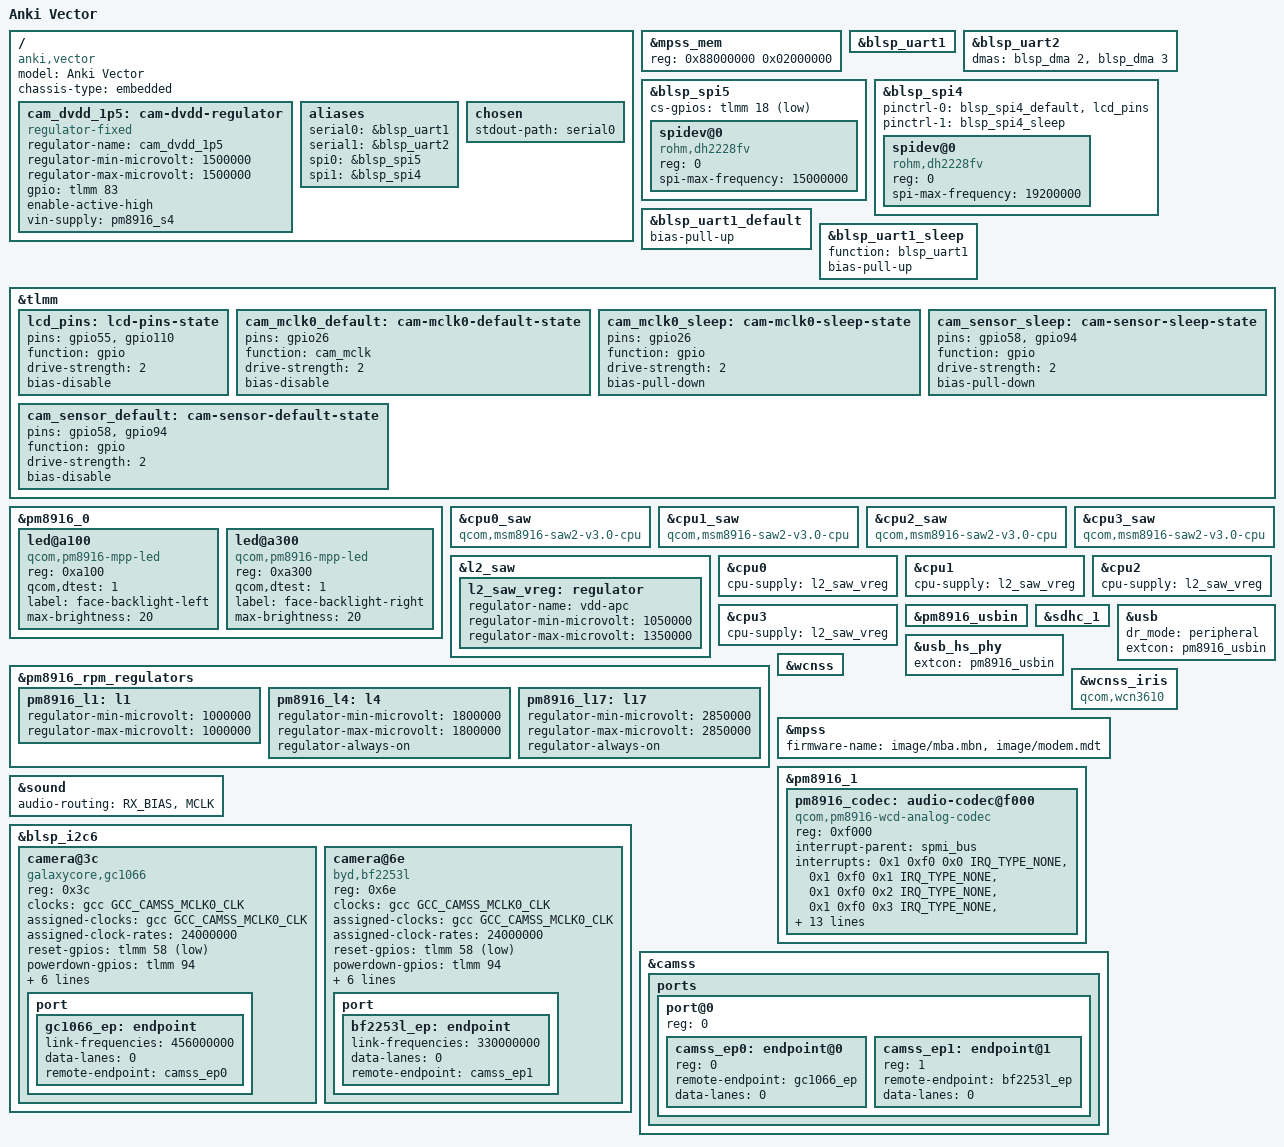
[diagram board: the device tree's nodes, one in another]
// SPDX-License-Identifier: GPL-2.0-only

/dts-v1/;

#include "qcom-msm8909-pm8916.dtsi"
#include "qcom-apq8009-modem-qdsp6.dtsi"

#include <dt-bindings/clock/qcom,gcc-msm8909.h>
#include <dt-bindings/gpio/gpio.h>
#include <dt-bindings/input/input.h>
#include <dt-bindings/interrupt-controller/irq.h>
#include <dt-bindings/leds/common.h>
#include <dt-bindings/pinctrl/qcom,pmic-mpp.h>

/ {
	model = "Anki Vector";
	compatible = "anki,vector", "qcom,msm8909";
	chassis-type = "embedded";

	// there's an external regulator for the camera
	// i can't say i understand why
	// S4 is 2.05V, VOUT (cam VDD) is 1.50V
	// GPIO 83 -> EN
	cam_dvdd_1p5: cam-dvdd-regulator {
		compatible = "regulator-fixed";
		regulator-name = "cam_dvdd_1p5";
		regulator-min-microvolt = <1500000>;
		regulator-max-microvolt = <1500000>;
		gpio = <&tlmm 83 GPIO_ACTIVE_HIGH>;
		enable-active-high;
		vin-supply = <&pm8916_s4>;
	};

	aliases {
		serial0 = &blsp_uart1; // kernel logs and shell
		serial1 = &blsp_uart2; // body
		spi0 = &blsp_spi5; // imu
		spi1 = &blsp_spi4; // lcd
	};

	chosen {
		#address-cells = <1>;
		#size-cells = <1>;
		ranges;

		stdout-path = "serial0";
	};
};

// the original firmware spanned EIGHTY FIVE MEGABYTES
// the firmware itself isn't this big, but it includes addresses which span this much
&mpss_mem {
	reg = <0x88000000 0x02000000>; // 32MB
};

// &bimc {
// 	status = "disabled";
// };

// &gcc {
// 	assigned-clocks = <&gcc BIMC_DDR_CLK_SRC>;
// 	assigned-clock-rates = <400000000>;
// };

&blsp_uart1 {
	status = "okay";
};

&blsp_uart2 {
	status = "okay";

	dmas = <&blsp_dma 2>, <&blsp_dma 3>;
	dma-names = "tx", "rx";
};

// imu
&blsp_spi5 {
	status = "okay";
	cs-gpios = <&tlmm 18 GPIO_ACTIVE_LOW>;

	spidev@0 {
        // the linux people don't like spidev
        // but Vector's software wants it.
        // only a few devices have exceptions.
        // this device is one of them
		compatible = "rohm,dh2228fv";
		reg = <0>;
		spi-max-frequency = <15000000>;
	};
};

// lcd
&blsp_spi4 {
	status = "okay";
	pinctrl-0 = <&blsp_spi4_default &lcd_pins>;
	pinctrl-1 = <&blsp_spi4_sleep>;

	spidev@0 {
		compatible = "rohm,dh2228fv";
		reg = <0>;
		spi-max-frequency = <19200000>;
	};
};

&blsp_uart1_default {
	/delete-property/ bias-disable;
	bias-pull-up;
};

&blsp_uart1_sleep {
	function = "blsp_uart1";
	/delete-property/ bias-pull-down;
	bias-pull-up;
};

// display reset and wrx
&tlmm {
	lcd_pins: lcd-pins-state {
		pins = "gpio55", "gpio110";
		function = "gpio";
		drive-strength = <2>;
		bias-disable;
	};

	cam_mclk0_default: cam-mclk0-default-state {
		pins = "gpio26";
		function = "cam_mclk";
		drive-strength = <2>;
		bias-disable;
	};

	cam_mclk0_sleep: cam-mclk0-sleep-state {
		pins = "gpio26";
		function = "gpio";
		drive-strength = <2>;
		bias-pull-down;
	};

	cam_sensor_default: cam-sensor-default-state {
		pins = "gpio58", "gpio94";
		function = "gpio";
		drive-strength = <2>;
		bias-disable;
	};

	cam_sensor_sleep: cam-sensor-sleep-state {
		pins = "gpio58", "gpio94";
		function = "gpio";
		drive-strength = <2>;
		bias-pull-down;
	};
};

&pm8916_0 {
	led@a100 {
		compatible = "qcom,pm8916-mpp-led";
		reg = <0xa100>;
		qcom,dtest = <1>;
		label = "face-backlight-left";
		max-brightness = <20>;
	};

	led@a300 {
		compatible = "qcom,pm8916-mpp-led";
		reg = <0xa300>;
		qcom,dtest = <1>;
		label = "face-backlight-right";
		max-brightness = <20>;
	};
};

// vector uses a pm8916
&cpu0_saw { compatible = "qcom,msm8916-saw2-v3.0-cpu", "qcom,saw2"; };
&cpu1_saw { compatible = "qcom,msm8916-saw2-v3.0-cpu", "qcom,saw2"; };
&cpu2_saw { compatible = "qcom,msm8916-saw2-v3.0-cpu", "qcom,saw2"; };
&cpu3_saw { compatible = "qcom,msm8916-saw2-v3.0-cpu", "qcom,saw2"; };

&l2_saw {
	l2_saw_vreg: regulator {
		regulator-name = "vdd-apc";
		regulator-min-microvolt = <1050000>;
		regulator-max-microvolt = <1350000>;
	};
};

&cpu0 { cpu-supply = <&l2_saw_vreg>; };
&cpu1 { cpu-supply = <&l2_saw_vreg>; };
&cpu2 { cpu-supply = <&l2_saw_vreg>; };
&cpu3 { cpu-supply = <&l2_saw_vreg>; };

&pm8916_usbin {
	status = "okay";
};

&sdhc_1 {
	status = "okay";
};

&pm8916_rpm_regulators {
	pm8916_l1: l1 {
		regulator-min-microvolt = <1000000>;
		regulator-max-microvolt = <1000000>;
	};

	pm8916_l4: l4 {
		regulator-min-microvolt = <1800000>;
		regulator-max-microvolt = <1800000>;
		regulator-always-on;
	};

	pm8916_l17: l17 {
		regulator-min-microvolt = <2850000>;
		regulator-max-microvolt = <2850000>;
		regulator-always-on; // display AVDD
	};
};

&usb {
	dr_mode = "peripheral";
	extcon = <&pm8916_usbin>;
	status = "okay";
};

&usb_hs_phy {
	extcon = <&pm8916_usbin>;
	status = "okay";
};

&wcnss {
	status = "okay";
};

&wcnss_iris {
	compatible = "qcom,wcn3610";
};

&mpss {
	firmware-name = "image/mba.mbn", "image/modem.mdt";
};

&pm8916_1 {
	pm8916_codec: audio-codec@f000 {
		compatible = "qcom,pm8916-wcd-analog-codec";
		reg = <0xf000>;
		status = "okay";
		interrupt-parent = <&spmi_bus>;
		interrupts = <0x1 0xf0 0x0 IRQ_TYPE_NONE>,
			     <0x1 0xf0 0x1 IRQ_TYPE_NONE>,
			     <0x1 0xf0 0x2 IRQ_TYPE_NONE>,
			     <0x1 0xf0 0x3 IRQ_TYPE_NONE>,
			     <0x1 0xf0 0x4 IRQ_TYPE_NONE>,
			     <0x1 0xf0 0x5 IRQ_TYPE_NONE>,
			     <0x1 0xf0 0x6 IRQ_TYPE_NONE>,
			     <0x1 0xf0 0x7 IRQ_TYPE_NONE>,
			     <0x1 0xf1 0x0 IRQ_TYPE_NONE>,
			     <0x1 0xf1 0x1 IRQ_TYPE_NONE>,
			     <0x1 0xf1 0x2 IRQ_TYPE_NONE>,
			     <0x1 0xf1 0x3 IRQ_TYPE_NONE>,
			     <0x1 0xf1 0x4 IRQ_TYPE_NONE>,
			     <0x1 0xf1 0x5 IRQ_TYPE_NONE>;
		interrupt-names = "cdc_spk_cnp_int",
				  "cdc_spk_clip_int",
				  "cdc_spk_ocp_int",
				  "mbhc_ins_rem_det1",
				  "mbhc_but_rel_det",
				  "mbhc_but_press_det",
				  "mbhc_ins_rem_det",
				  "mbhc_switch_int",
				  "cdc_ear_ocp_int",
				  "cdc_hphr_ocp_int",
				  "cdc_hphl_ocp_det",
				  "cdc_ear_cnp_int",
				  "cdc_hphr_cnp_int",
				  "cdc_hphl_cnp_int";
		vdd-cdc-io-supply = <&pm8916_l5>;
		vdd-cdc-tx-rx-cx-supply = <&pm8916_l5>;
		vdd-micbias-supply = <&pm8916_l13>;
		#sound-dai-cells = <1>;
	};
};

&sound {
	audio-routing =
		"RX_BIAS", "MCLK";
};

&blsp_i2c6 {
	status = "okay";

	// 1.0
	camera@3c {
		compatible = "galaxycore,gc1066";
		reg = <0x3c>;

		clocks = <&gcc GCC_CAMSS_MCLK0_CLK>;
		clock-names = "xvclk";

		assigned-clocks = <&gcc GCC_CAMSS_MCLK0_CLK>;
		assigned-clock-rates = <24000000>;

		reset-gpios = <&tlmm 58 GPIO_ACTIVE_LOW>;
		powerdown-gpios = <&tlmm 94 GPIO_ACTIVE_HIGH>;

		avdd-supply = <&pm8916_l17>;
		vddio-supply = <&pm8916_l4>;
		dvdd-supply = <&cam_dvdd_1p5>;

		pinctrl-names = "default", "sleep";
		pinctrl-0 = <&cam_mclk0_default &cam_sensor_default>;
		pinctrl-1 = <&cam_mclk0_sleep &cam_sensor_sleep>;

		port {
			gc1066_ep: endpoint {
				link-frequencies = /bits/ 64 <456000000>;
				data-lanes = <0>;
				remote-endpoint = <&camss_ep0>;
			};
		};
	};

	// 2.0
	camera@6e {
		compatible = "byd,bf2253l";
		reg = <0x6e>;

		clocks = <&gcc GCC_CAMSS_MCLK0_CLK>;
		clock-names = "xvclk";

		assigned-clocks = <&gcc GCC_CAMSS_MCLK0_CLK>;
		assigned-clock-rates = <24000000>;

		reset-gpios = <&tlmm 58 GPIO_ACTIVE_LOW>;
		powerdown-gpios = <&tlmm 94 GPIO_ACTIVE_HIGH>;

		avdd-supply = <&pm8916_l17>;
		vddio-supply = <&pm8916_l4>;
		dvdd-supply = <&cam_dvdd_1p5>;

		pinctrl-names = "default", "sleep";
		pinctrl-0 = <&cam_mclk0_default &cam_sensor_default>;
		pinctrl-1 = <&cam_mclk0_sleep &cam_sensor_sleep>;

		port {
			bf2253l_ep: endpoint {
				link-frequencies = /bits/ 64 <330000000>;
				data-lanes = <0>;
				remote-endpoint = <&camss_ep1>;
			};
		};
	};
};

&camss {
	status = "okay";

	ports {
		port@0 {
			reg = <0>;

			camss_ep0: endpoint@0 {
				reg = <0>;
				remote-endpoint = <&gc1066_ep>;
				data-lanes = <0>;
			};

			camss_ep1: endpoint@1 {
				reg = <1>;
				remote-endpoint = <&bf2253l_ep>;
				data-lanes = <0>;
			};
		};
	};
};
